# tviic2d6mddr register map
Vendor: Cypress Semiconductor; Series: tviic2d6mddr; File version: 1.0
CPU: CM7 r0p1, little endian, MPU, FPU, VTOR, 3 interrupt priority bits
Registers are 32-bit, read-write, reset 0x0 unless marked. A register's access mark holds for its fields unless they carry their own. Offsets are from the block's base; [hi:lo] are bit positions; lines under a group give offsets from that group; {n}, {i} and the like mark numbered series; 'fields as' and 'values as' point back to an identical list.

## LPDDR40 (part 4 of 5) — LPDDR4
Base 0x404A0000
0x1000 LPDDR4_CORE group — LPDDR4 core (3PIP)
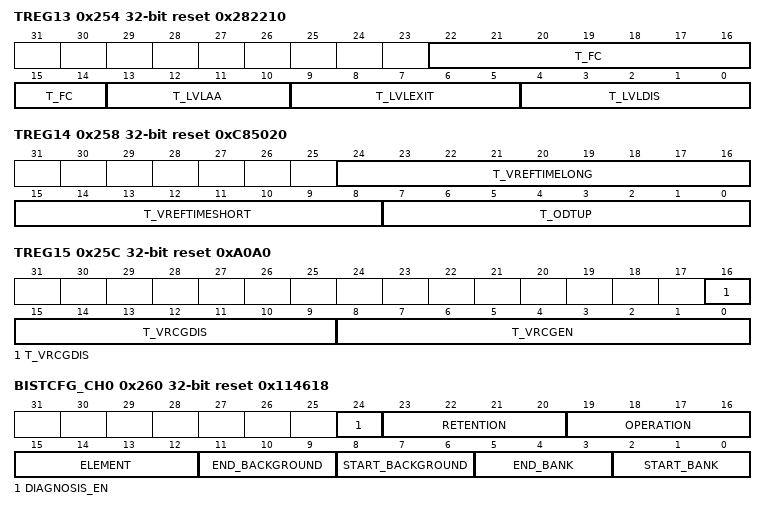
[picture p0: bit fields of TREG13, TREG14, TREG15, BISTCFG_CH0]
  0x254 TREG13 reset 0x282210 — Timing Register 13
    [22:14] T_FC — Frequency Set Point Switching Time = 'ha0
    [13:10] T_LVLAA — Leveling command-to-command/strobe-to-strobe delay. For read training, specifies the minimum number of DFI clock cycles after the assertion of a RD/MRR command to the next RD/MRR command. For write leveling, specifies the minimum number of DFI clock cycles after the assertion of the dfi_wrlvl_strobe signal to the next dfi_wrlvl_strobe signal assertion. = 8
    [9:5] T_LVLEXIT — Leveling exit time, specifies the minimum number of DFI clock cycles after the de-assertion of the DTI_*LVL_EN signal to the MRS command to disable DDR training. = 20
    [4:0] T_LVLDIS — Leveling disable time, specifies the minimum number of DFI clock cycles after the PHY asserts training status signal to the de-assert of DTI_*LVL_EN. = 8
  0x258 TREG14 reset 0xC85020 — Timing Register 14
    [24:16] T_VREFTIMELONG — VREF changing time for multiple steps >= RU(tVREFca_Long/tfs_period)
    [15:8] T_VREFTIMESHORT — VREF changing time for single steps. >= RU(tVREFca_Short/tfs_period)
    [7:0] T_ODTUP
  0x25C TREG15 reset 0xA0A0 — Timing Register 15
    [16:9] T_VRCGDIS — VREF high current mode disable time = 8'h53
    [8:0] T_VRCGEN — VREF high current mode enable time = 9'ha3
  0x260 BISTCFG_CH0 reset 0x114618 — BIST Configuration Register - Channel 0
    [24] DIAGNOSIS_EN — Enable diagnosis mode - Channel 0 Enable/disable coding: DISABLE = 0 Disable this feature ENABLE = 1 Enable this feature
    [23:20] RETENTION — Count-to value of retention counter (Width = RETENTION_WIDTH) - Channel 0
    [19:16] OPERATION — March operation number - Channel 0
    [15:12] ELEMENT — March element number - Channel 0
    [11:9] END_BACKGROUND — End background index - Channel 0
    [8:6] START_BACKGROUND — Start background index - Channel 0
    [5:3] END_BANK — End bank (Width = DRAM_BANK_WIDTH) - Channel 0
    [2:0] START_BANK — Start bank (Width = DRAM_BANK_WIDTH) - Channel 0
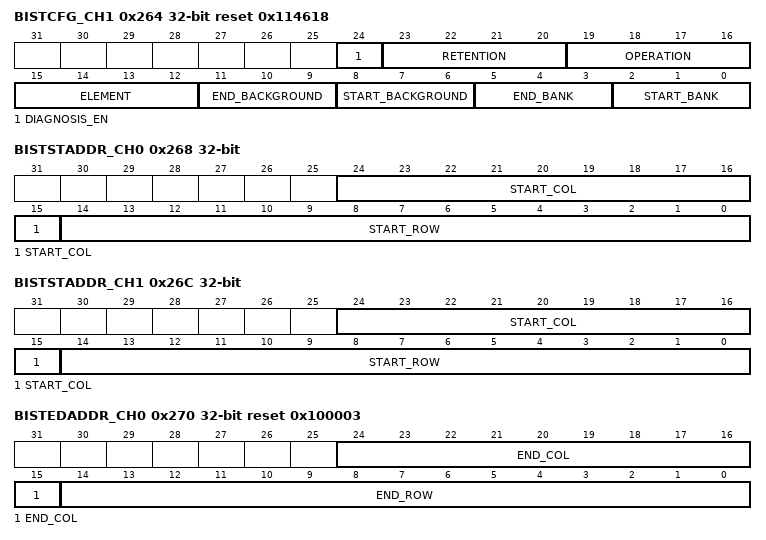
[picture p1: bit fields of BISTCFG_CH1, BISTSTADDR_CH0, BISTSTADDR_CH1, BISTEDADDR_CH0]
  0x264 BISTCFG_CH1 reset 0x114618 — BIST Configuration Register - Channel 1
    [24] DIAGNOSIS_EN — Enable diagnosis mode - Channel 1 Enable/disable coding: DISABLE = 0 Disable this feature ENABLE = 1 Enable this feature
    [23:20] RETENTION — Count-to value of retention counter (Width = RETENTION_WIDTH) - Channel 1
    [19:16] OPERATION — March operation number - Channel 1
    [15:12] ELEMENT — March element number - Channel 1
    [11:9] END_BACKGROUND — End background index - Channel 1
    [8:6] START_BACKGROUND — Start background index - Channel 1
    [5:3] END_BANK — End bank (Width = DRAM_BANK_WIDTH) - Channel 1
    [2:0] START_BANK — Start bank (Width = DRAM_BANK_WIDTH) - Channel 1
  0x268 BISTSTADDR_CH0 — BIST Start Address - Channel 0
    [24:15] START_COL — Start column address (Width = DRAM_COL_WIDTH) - Channel 0
    [14:0] START_ROW — Start row address (Width = DRAM_ROW_WIDTH) - Channel 0
  0x26C BISTSTADDR_CH1 — BIST Start Address - Channel 1
    [24:15] START_COL — Start column address (Width = DRAM_COL_WIDTH) - Channel 1
    [14:0] START_ROW — Start row address (Width = DRAM_ROW_WIDTH) - Channel 1
  0x270 BISTEDADDR_CH0 reset 0x100003 — BIST End Address - Channel 0
    [24:15] END_COL — End column address (Width = DRAM_COL_WIDTH) - Channel 0
    [14:0] END_ROW — End row address (Width = DRAM_ROW_WIDTH) - Channel 0
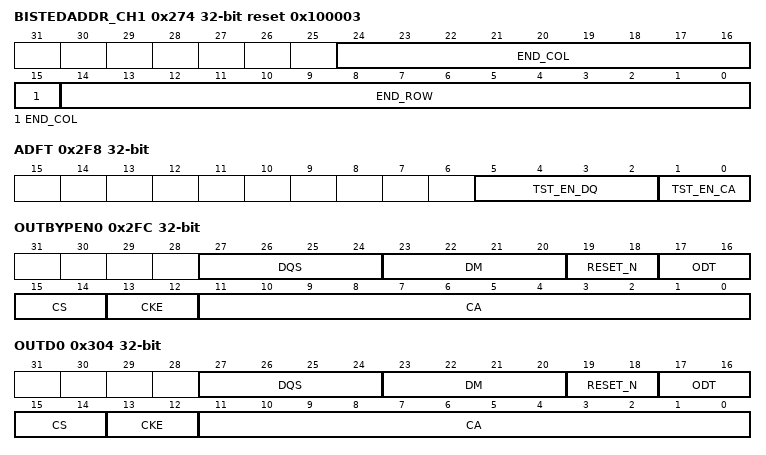
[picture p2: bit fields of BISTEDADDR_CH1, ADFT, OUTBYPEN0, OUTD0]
  0x274 BISTEDADDR_CH1 reset 0x100003 — BIST End Address - Channel 1
    [24:15] END_COL — End column address (Width = DRAM_COL_WIDTH) - Channel 1
    [14:0] END_ROW — End row address (Width = DRAM_ROW_WIDTH) - Channel 1
  0x278 BISTM0_CH0 reset 0x92000000 — BIST March Element Register 0 - Channel 0
    [31:0] MARCH_ELEMENT_0 — March element 0 - Channel 0
  0x27C BISTM0_CH1 reset 0x92000000 — BIST March Element Register 0 - Channel 1
    [31:0] MARCH_ELEMENT_0 — March element 0 - Channel 1
  0x280 BISTM1_CH0 reset 0xA0000000 — BIST March Element Register 1 - Channel 0
    [31:0] MARCH_ELEMENT_1 — March element 1 - Channel 0
  0x284 BISTM1_CH1 reset 0xA0000000 — BIST March Element Register 1 - Channel 1
    [31:0] MARCH_ELEMENT_1 — March element 1 - Channel 1
  0x288 BISTM2_CH0 reset 0xCA800000 — BIST March Element Register 2 - Channel 0
    [31:0] MARCH_ELEMENT_2 — March element 2 - Channel 0
  0x28C BISTM2_CH1 reset 0xCA800000 — BIST March Element Register 2 - Channel 1
    [31:0] MARCH_ELEMENT_2 — March element 2 - Channel 1
  0x290 BISTM3_CH0 reset 0x20000000 — BIST March Element Register 3 - Channel 0
    [31:0] MARCH_ELEMENT_3 — March element 3 - Channel 0
  0x294 BISTM3_CH1 reset 0x20000000 — BIST March Element Register 3 - Channel 1
    [31:0] MARCH_ELEMENT_3 — March element 3 - Channel 1
  0x298 BISTM4_CH0 reset 0x4E000000 — BIST March Element Register 4 - Channel 0
    [31:0] MARCH_ELEMENT_4 — March element 4 - Channel 0
  0x29C BISTM4_CH1 reset 0x4E000000 — BIST March Element Register 4 - Channel 1
    [31:0] MARCH_ELEMENT_4 — March element 4 - Channel 1
  {0x278+8j} BISTM{j}_CH0 (j=5..15) — BIST March Element Register {j} - Channel 0
    [31:0] MARCH_ELEMENT_{j} — March element {j} - Channel 0
  {0x27C+8j} BISTM{j}_CH1 (j=5..15) — BIST March Element Register {j} - Channel 1
    [31:0] MARCH_ELEMENT_{j} — March element {j} - Channel 1
  0x2F8 ADFT
    [5:2] TST_EN_DQ — Test enable for ADFT bus - DQ Blocks adft_tst_en_dq[0]: if set to 1: enable for VREF of Data Slice 0 adft_tst_en_dq[1]: if set to 1: enable for VREF of Data Slice 1 adft_tst_en_dq[2]: if set to 1: enable for VREF of Data Slice 2 adft_tst_en_dq[3]: if set to 1: enable for VREF of Data Slice 3
    [1:0] TST_EN_CA — Test enable for ADFT bus - Control Block adft_tst_en_ca[0]: if set to 1: enable for VREF of channel A adft_tst_en_ca[1]: if set to 1: enable for VREF of channel B
  0x2FC OUTBYPEN0 — Output Bypass Enable Register 0
    [27:24] DQS — Output Bypass Enable for DQS bus When a bit in register OUTBYPEN* is set to 1, the value of the corresponding bit in register OUTD* is asserted at the output.
    [23:20] DM — Output Bypass Enable for DM bus When a bit in register OUTBYPEN* is set to 1, the value of the corresponding bit in register OUTD* is asserted at the output.
    [19:18] RESET_N — Output Bypass Enable for RESET_N bus When a bit in register OUTBYPEN* is set to 1, the value of the corresponding bit in register OUTD* is asserted at the output.
    [17:16] ODT — Output Bypass Enable for ODT bus When a bit in register OUTBYPEN* is set to 1, the value of the corresponding bit in register OUTD* is asserted at the output.
    [15:14] CS — Output Bypass Enable for CS bus When a bit in register OUTBYPEN* is set to 1, the value of the corresponding bit in register OUTD* is asserted at the output.
    [13:12] CKE — Output Bypass Enable for CKE bus When a bit in register OUTBYPEN* is set to 1, the value of the corresponding bit in register OUTD* is asserted at the output.
    [11:0] CA — Output Bypass Enable for CA bus When a bit in register OUTBYPEN* is set to 1, the value of the corresponding bit in register OUTD* is asserted at the output.
  0x300 OUTBYPEN1 — Output Bypass Enable Register 1
    [31:0] DQ — Output Data Input for DQ bus When a bit in register OUTBYPEN* is set to 1, the value of the corresponding bit in register OUTD* is asserted at the output.
  0x304 OUTD0 — Output Data In Register 0
    [27:24] DQS — Output Data Input for DQS bus When a bit in register OUTBYPEN* is set to 1, the value of the corresponding bit in register OUTD* is asserted at the output.
    [23:20] DM — Output Data Input for DM bus When a bit in register OUTBYPEN* is set to 1, the value of the corresponding bit in register OUTD* is asserted at the output.
    [19:18] RESET_N — Output Data Input for RESET_N bus When a bit in register OUTBYPEN* is set to 1, the value of the corresponding bit in register OUTD* is asserted at the output.
    [17:16] ODT — Output Data Input for ODT bus When a bit in register OUTBYPEN* is set to 1, the value of the corresponding bit in register OUTD* is asserted at the output.
    [15:14] CS — Output Data Input for CS bus When a bit in register OUTBYPEN* is set to 1, the value of the corresponding bit in register OUTD* is asserted at the output.
    [13:12] CKE — Output Data Input for CKE bus When a bit in register OUTBYPEN* is set to 1, the value of the corresponding bit in register OUTD* is asserted at the output.
    [11:0] CA — Output Data Input for CA bus When a bit in register OUTBYPEN* is set to 1, the value of the corresponding bit in register OUTD* is asserted at the output.
  0x308 OUTD1 — Output Data In Register 1
    fields as LPDDR4_CORE.OUTBYPEN1
  0x30C INECC0 — Inline ECC Register 0
    [29:0] ECC_BASE — ECC Region Base Address
  0x310 INECC1 — Inline ECC Register 1
    [29:0] PROT_MEM_BASE — Protected Region Base Address
  0x314 INECC2 — Inline ECC Register 2
    [29:0] PROT_MEM_SIZE — Protected Region Size (Bytes)
  0xE00 DVSTT0 ro — Device ID Status Register
    [15:0] DEVICE_ID — 6 bits - Version, 5 bits - Reversion, 5 bits - Release
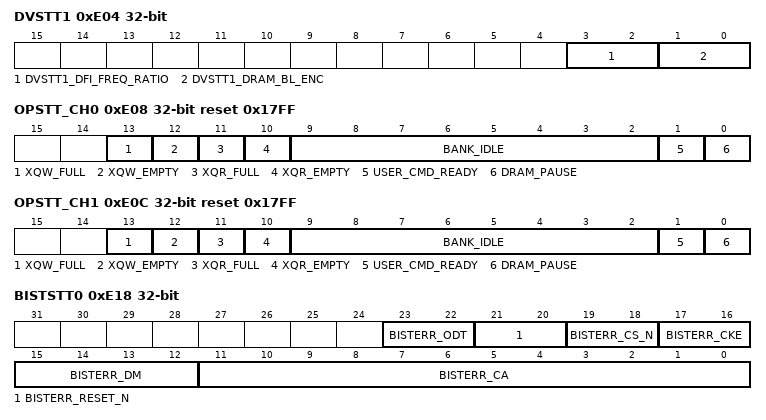
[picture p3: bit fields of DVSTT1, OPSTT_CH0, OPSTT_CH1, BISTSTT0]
  0xE04 DVSTT1 ro — Device Mode Status Register
    [3:2] DVSTT1_DFI_FREQ_RATIO — DFI frequency ratio. FREQ_RATIO_DIV4 = 2'b10 Always read 2'b10 as frequency ratio controller : PHY is fixed to 1:4
    [1:0] DVSTT1_DRAM_BL_ENC
  0xE08 OPSTT_CH0 ro reset 0x17FF — Operation Status Register 1 - Channel 0
    [13] XQW_FULL — Write Path Cross-over Queue Full - Channel 0
    [12] XQW_EMPTY — Write Path Cross-over Queue Empty - Channel 0
    [11] XQR_FULL — Read Path Cross-over Queue Full - Channel 0
    [10] XQR_EMPTY — Read Path Cross-over Queue Empty - Channel 0
    [9:2] BANK_IDLE — Bank Controller Idle (8 banks) - Channel 0
    [1] USER_CMD_READY — User Command Ready - Channel 0
    [0] DRAM_PAUSE — DRAM Paused for PD - Channel 0
  0xE0C OPSTT_CH1 ro reset 0x17FF — Operation Status Register 1 - Channel 1
    [13] XQW_FULL — Write Path Cross-over Queue Full - Channel 1
    [12] XQW_EMPTY — Write Path Cross-over Queue Empty - Channel 1
    [11] XQR_FULL — Read Path Cross-over Queue Full - Channel 1
    [10] XQR_EMPTY — Read Path Cross-over Queue Empty - Channel 1
    [9:2] BANK_IDLE — Bank Controller Idle (8 banks) - Channel 1
    [1] USER_CMD_READY — User Command Ready - Channel 1
    [0] DRAM_PAUSE — DRAM Paused for PD - Channel 1
  0xE10 INTSTT_CH0 ro — Interrupt Status Register - Channel 0
    [0] INT_GC_FSM — Global Control FSM Error Interrupt Status - Channel 0
  0xE14 INTSTT_CH1 ro — Interrupt Status Register - Channel 1
    [0] INT_GC_FSM — Global Control FSM Error Interrupt Status - Channel 1
  0xE18 BISTSTT0 ro — BIST Status 0
    [23:22] BISTERR_ODT — BIST Error status of ODT A '1' indicates an error on the respective ODT line.
    [21:20] BISTERR_RESET_N — BIST Error status of RESET_N A '1' indicates an error on the respective RST line.
    [19:18] BISTERR_CS_N — BIST Error status of CS_N A '1' indicates an error on the respective CS line.
    [17:16] BISTERR_CKE — BIST Error status of CKE A '1' indicates an error on the respective CKE line.
    [15:12] BISTERR_DM — BIST Error status of DM A '1' indicates an error on the respective DM line.
    [11:0] BISTERR_CA — BIST Error status of CA A '1' indicates an error on the respective CA line.
  0xE1C BISTSTT1 ro — BIST Status 1
    [31:0] BISTERR_DQ — BIST Error status of DQ Data Range A '1' indicates an error on the respective DQ line.
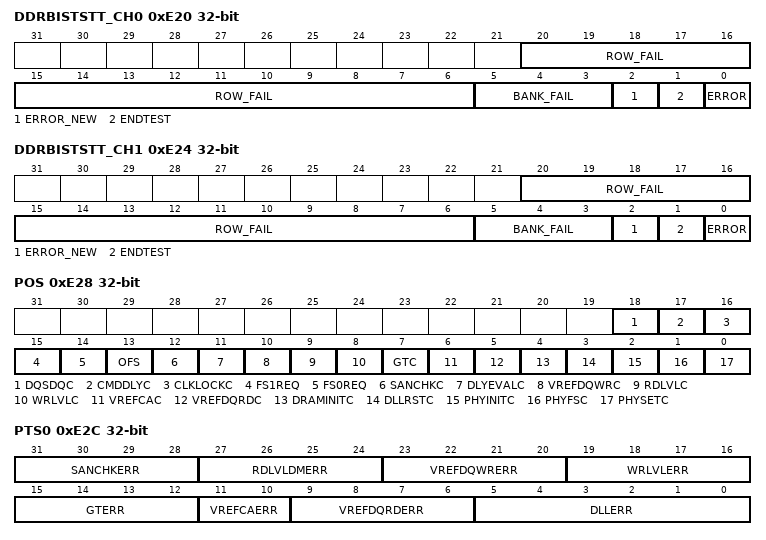
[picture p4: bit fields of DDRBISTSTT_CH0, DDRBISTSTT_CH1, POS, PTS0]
  0xE20 DDRBISTSTT_CH0 ro — DDR BIST Status Register - Channel 0
    [20:6] ROW_FAIL — Failed row address in diagnosis mode (Width = DRAM_ROW_WIDTH) - Channel 0
    [5:3] BANK_FAIL — Failed bank address in diagnosis mode (Width = DRAM_BANK_WIDTH) - Channel 0
    [2] ERROR_NEW — New BIST error in diagnosis mode - Channel 0
    [1] ENDTEST — BIST endtest - Channel 0
    [0] ERROR — BIST error - Channel 0
  0xE24 DDRBISTSTT_CH1 ro — DDR BIST Status Register - Channel 1
    [20:6] ROW_FAIL — Failed row address in diagnosis mode (Width = DRAM_ROW_WIDTH) - Channel 1
    [5:3] BANK_FAIL — Failed bank address in diagnosis mode (Width = DRAM_BANK_WIDTH) - Channel 1
    [2] ERROR_NEW — New BIST error in diagnosis mode - Channel 1
    [1] ENDTEST — BIST endtest - Channel 1
    [0] ERROR — BIST error - Channel 1
  0xE28 POS ro — PHY Operation Status Register
    [18] DQSDQC — tDQS2DQ training completed for rank 0
    [17] CMDDLYC — PHY command bus delay loaded
    [16] CLKLOCKC — MC-PHY clock phase locked.
    [15] FS1REQ — Frequency set point 1 request.
    [14] FS0REQ — Frequency set point 0 request.
    [13] OFS — Operating frequency set point.
    [12] SANCHKC — Write/read sanity check completed for rank 0
    [11] DLYEVALC — Delay evaluation completed for rank 0
    [10] VREFDQWRC — DRAM VREF-DQ training completed for rank 0
    [9] RDLVLC — Read data eye training completed for rank 0
    [8] WRLVLC — Write leveling completed for rank 0
    [7] GTC — Gate training completed for rank 0
    [6] VREFCAC — DRAM VREF-CA training completed.
    [5] VREFDQRDC — PHY VREF-DQ training completed.
    [4] DRAMINITC — DRAM initialization completed.
    [3] DLLRSTC — DLL reset completed.
    [2] PHYINITC — PHY initialization completed
    [1] PHYFSC — PHY frequency change completed.
    [0] PHYSETC — PHY setting reload completed.
  0xE2C PTS0 ro — PHY Training Status Register 0
    [31:28] SANCHKERR — Write/Read sanity check error on rank 0. One bit for each data slice. 1 means read pattern and write pattern for corresponding data slice are not match
    [27:24] RDLVLDMERR — DM read data eye training error on rank 0. One bit for each DM signal. 1 means data eye training for corresponding DM is not completed successfully
    [23:20] VREFDQWRERR — Write VREF-DQ training error on rank 0. One bit for each data slice. 1 means VREF training for DRAM is not completed successfully
    [19:16] WRLVLERR — Write leveling error on rank 0. One bit for each data slice. 1 means write leveling is not completed successfully
    [15:12] GTERR — Gate training error on rank 0. One bit for each data slice. 1 means gate training is not completed successfully
    [11:10] VREFCAERR — VREFCA training error on rank 0. vrefcaerr[1] is for LPDDR4 channel B and vrefcaerr[0] is for LPDDR4 channel A. 1 means VREFCA training for corresponding LPDDR4 channel is not completed successfully
    [9:6] VREFDQRDERR — Read VREF-DQ training error on rank 0. One bit for each data slice. 1 means PHY cannot find suitable VREF setting for its receiver
    [5:0] DLLERR — DLL reset error. Dllerr[3:0] is for data module [3:0], and dllerr[5:4] is for control module[1:0]. 1 means the DLL reset process of corresponding module is not completed successfully.
  0xE30 PTS1 ro — PHY Training Status Register 1
    [31:0] RDLVLDQERR — DQ read data eye training error on rank 0. One bit for each DQ signal. 1 means data eye training for corresponding DQ signal is not completed successfully.
  0xE34 PTS2 ro — PHY Training Status Register 2
    [31:0] DQSDQERR — DQS-DQ training error on rank 0. One bit for each DQ signal. 1 means data eye training for corresponding DQ signal is not completed successfully.
  0xE38 PTS3 ro — PHY Training Status Register 3
    [3:0] DQSDMERR — DQS-DM training error on rank 0. One bit for each DM signal. 1 means data eye training for corresponding DM signal is not completed successfully.
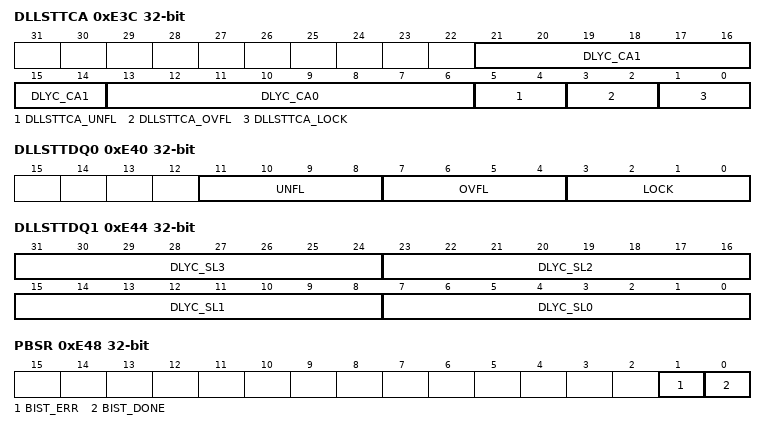
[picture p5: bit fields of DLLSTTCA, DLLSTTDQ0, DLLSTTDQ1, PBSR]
  0xE3C DLLSTTCA ro — DLL Status Register for PHY Command Module
    [21:14] DLYC_CA1 — DLL delay code for Channel B
    [13:6] DLYC_CA0 — DLL delay code for Channel A
    [5:4] DLLSTTCA_UNFL — Underflow status. This output is set when a quarter of the clock cycle is less than the shortest delay that the delay chain can handle.
    [3:2] DLLSTTCA_OVFL — Overflow status. This output is set when a quarter of the clock cycle is greater than the largest delay that the delay chain can handle.
    [1:0] DLLSTTCA_LOCK — DLL lock status.
  0xE40 DLLSTTDQ0 ro — DLL Status Register for PHY Data Module 0
    [11:8] UNFL — Underflow status. This output is set when a quarter of the clock cycle is less than the shortest delay that the delay chain can handle. One bit for each Data Slice.
    [7:4] OVFL — Overflow status. This output is set when a quarter of the clock cycle is greater than the largest delay that the delay chain can handle. One bit for each Data Slice.
    [3:0] LOCK — DLL lock status. One bit for each Data Slice.
  0xE44 DLLSTTDQ1 ro — DLL Status Register for PHY Data Module 1
    [8n+7:8n] DLYC_SL{n} (n=0..3) — DLL delay code DQ Slice {n}
  0xE48 PBSR ro — PHY BIST Status Register
    [1] BIST_ERR — PHY BIST error status
    [0] BIST_DONE — PHY BIST done status
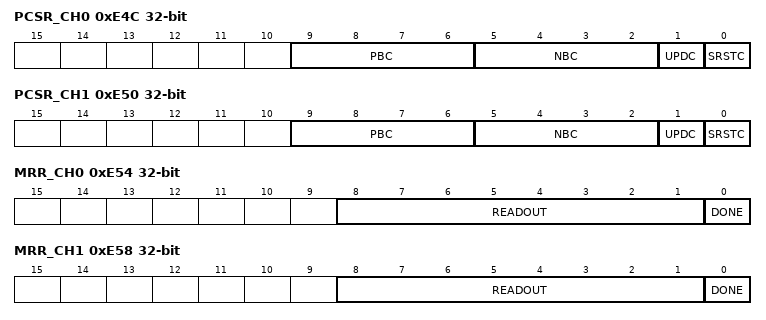
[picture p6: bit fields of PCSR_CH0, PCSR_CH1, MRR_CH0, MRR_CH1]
  0xE4C PCSR_CH0 ro — PHY Compensation Status Register - Channel 0
    [9:6] PBC — Impedance pull-up settings observation bits - Channel 0
    [5:2] NBC — Impedance pull-down settings observation bits - Channel 0
    [1] UPDC — Indicates if settings of the compensation were updated - Channel 0
    [0] SRSTC — Compensation soft-restart completed - Channel 0
  0xE50 PCSR_CH1 ro — PHY Compensation Status Register - Channel 1
    [9:6] PBC — Impedance pull-up settings observation bits - Channel 1
    [5:2] NBC — Impedance pull-down settings observation bits - Channel 1
    [1] UPDC — Indicates if settings of the compensation were updated - Channel 1
    [0] SRSTC — Compensation soft-restart completed - Channel 1
  0xE54 MRR_CH0 ro — MR Readout Register - Channel 0
    [8:1] READOUT — MRR data - Channel 0
    [0] DONE — MRR complete - Channel 0
  0xE58 MRR_CH1 ro — MR Readout Register - Channel 1
    [8:1] READOUT — MRR data - Channel 1
    [0] DONE — MRR complete - Channel 1
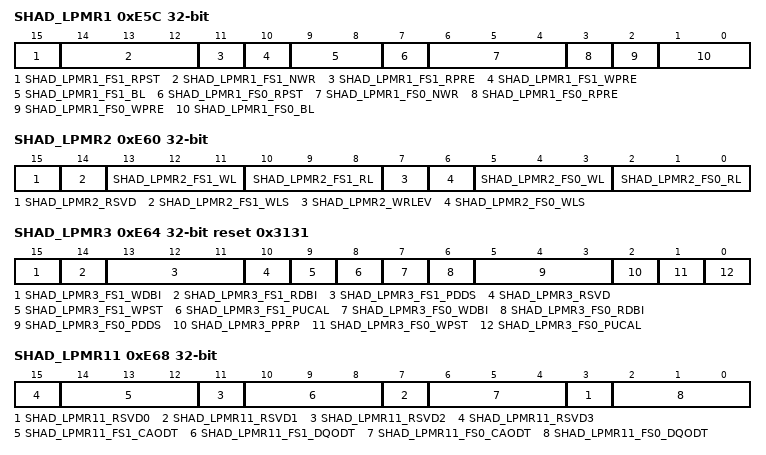
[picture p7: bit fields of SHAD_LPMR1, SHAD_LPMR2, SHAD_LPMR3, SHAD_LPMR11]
  0xE5C SHAD_LPMR1 ro — Shadow LPDDR Mode Register 1
    [15] SHAD_LPMR1_FS1_RPST — Shadow Read postamble FS1 Read Postamble values according to JESD209-4: RD_POSTAMBLE_0P5 = 0B RD Post-amble = 0.5*tCK (default) RD_POSTAMBLE_1P5 = 1B RD Post-amble = 1.5*tCK
    [14:12] SHAD_LPMR1_FS1_NWR — Shadow Write recovery to pre-charge FS1 Write Recovery values according to JESD209-4: NWR6 = 000B nWR = 6 (default) NWR10 = 001B nWR = 10 NWR16 = 010B nWR = 16 NWR20 = 011B nWR = 20 NWR24 = 100B nWR = 24 NWR30 = 101B nWR = 30 NWR34 = 110B nWR = 34 NWR40 = 111B nWR = 40
    [11] SHAD_LPMR1_FS1_RPRE — Shadow Read preamble FS1 Read Preamble values according to JESD209-4: RD_PREAMBLE_STATIC = 0B RD Pre-amble = Static (default) RD_PREAMBLE_TOGGLE = 1B RD Pre-amble = Toggle
    [10] SHAD_LPMR1_FS1_WPRE
    [9:8] SHAD_LPMR1_FS1_BL
    [7] SHAD_LPMR1_FS0_RPST — Shadow Read postamble FS0 Read Postamble values according to JESD209-4: RD_POSTAMBLE_0P5 = 0B RD Post-amble = 0.5*tCK (default) RD_POSTAMBLE_1P5 = 1B RD Post-amble = 1.5*tCK
    [6:4] SHAD_LPMR1_FS0_NWR — Shadow Write recovery to pre-charge FS0 Write Recovery values according to JESD209-4: NWR6 = 000B nWR = 6 (default) NWR10 = 001B nWR = 10 NWR16 = 010B nWR = 16 NWR20 = 011B nWR = 20 NWR24 = 100B nWR = 24 NWR30 = 101B nWR = 30 NWR34 = 110B nWR = 34 NWR40 = 111B nWR = 40
    [3] SHAD_LPMR1_FS0_RPRE — Shadow Read preamble FS0 Read Preamble values according to JESD209-4: RD_PREAMBLE_STATIC = 0B RD Pre-amble = Static (default) RD_PREAMBLE_TOGGLE = 1B RD Pre-amble = Toggle
    [2] SHAD_LPMR1_FS0_WPRE
    [1:0] SHAD_LPMR1_FS0_BL
  0xE60 SHAD_LPMR2 ro — Shadow LPDDR Mode Register 2
    [15] SHAD_LPMR2_RSVD
    [14] SHAD_LPMR2_FS1_WLS — Shadow Write latency set FS1 Values according to JESD209-4: WL_SET_A = 0B WL Set 'A' (default) WL_SET_B = 1B WL Set 'B'
    [13:11] SHAD_LPMR2_FS1_WL — Shadow Write latency FS1 Write Latency values according to JESD209-4: WL Set 'A' (MR2 OP[6]=0B) 000B: WL=4 (Default) 001B: WL=6 010B: WL=8 011B: WL=10 100B: WL=12 101B: WL=14 110B: WL=16 111B: WL=18 WL Set 'B' (MR2 OP[6]=1B) 000B: WL=4 001B: WL=8 010B: WL=12 011B: WL=18 100B: WL=22 101B: WL=26 110B: WL=30 111B: WL=34
    [10:8] SHAD_LPMR2_FS1_RL — Shadow Read latency FS1 Read Latency values according to JESD209-4: RL & nRTP for DBI-RD Disabled (MR3 OP[6]=0B) 000B: RL=6, nRTP = 8 (Default) 001B: RL=10, nRTP = 8 010B: RL=14, nRTP = 8 011B: RL=20, nRTP = 8 100B: RL=24, nRTP = 10 101B: RL=28, nRTP = 12 110B: RL=32, nRTP = 14 111B: RL=36, nRTP = 16 RL & nRTP for DBI-RD Enabled (MR3 OP[6]=1B) 000B: RL=6, nRTP = 8 001B: RL=12, nRTP = 8 010B: RL=16, nRTP = 8 011B: RL=22, nRTP = 8 100B: RL=28, nRTP = 10 101B: RL=32, nRTP = 12 110B: RL=36, nRTP = 14 111B: RL=40, nRTP = 16
    [7] SHAD_LPMR2_WRLEV — Shadow Write Leveling Enable FS0 Enable/disable coding: DISABLE = 0 Disable this feature ENABLE = 1 Enable this feature
    [6] SHAD_LPMR2_FS0_WLS — Shadow Write latency set FS0 Values according to JESD209-4: WL_SET_A = 0B WL Set 'A' (default) WL_SET_B = 1B WL Set 'B'
    [5:3] SHAD_LPMR2_FS0_WL — Shadow Write latency FS0 Write Latency values according to JESD209-4: WL Set 'A' (MR2 OP[6]=0B) 000B: WL=4 (Default) 001B: WL=6 010B: WL=8 011B: WL=10 100B: WL=12 101B: WL=14 110B: WL=16 111B: WL=18 WL Set 'B' (MR2 OP[6]=1B) 000B: WL=4 001B: WL=8 010B: WL=12 011B: WL=18 100B: WL=22 101B: WL=26 110B: WL=30 111B: WL=34
    [2:0] SHAD_LPMR2_FS0_RL — Shadow Read latency FS0 Read Latency values according to JESD209-4: RL & nRTP for DBI-RD Disabled (MR3 OP[6]=0B) 000B: RL=6, nRTP = 8 (Default) 001B: RL=10, nRTP = 8 010B: RL=14, nRTP = 8 011B: RL=20, nRTP = 8 100B: RL=24, nRTP = 10 101B: RL=28, nRTP = 12 110B: RL=32, nRTP = 14 111B: RL=36, nRTP = 16 RL & nRTP for DBI-RD Enabled (MR3 OP[6]=1B) 000B: RL=6, nRTP = 8 001B: RL=12, nRTP = 8 010B: RL=16, nRTP = 8 011B: RL=22, nRTP = 8 100B: RL=28, nRTP = 10 101B: RL=32, nRTP = 12 110B: RL=36, nRTP = 14 111B: RL=40, nRTP = 16
  0xE64 SHAD_LPMR3 ro reset 0x3131 — Shadow LPDDR Mode Register 3
    [15] SHAD_LPMR3_FS1_WDBI — Write DBI mode for frequency set 1 Values according to JESD209-4: Enable/disable coding: DISABLE = 0 Disable this feature ENABLE = 1 Enable this feature
    [14] SHAD_LPMR3_FS1_RDBI — Read DBI mode for frequency set 1 Values according to JESD209-4: Enable/disable coding: DISABLE = 0 Disable this feature ENABLE = 1 Enable this feature
    [13:11] SHAD_LPMR3_FS1_PDDS
    [10] SHAD_LPMR3_RSVD
    [9] SHAD_LPMR3_FS1_WPST — Write post-amble for frequency set 1 Write post-amble values according to JESD209-4: WR_POSTAMBLE_0P5 = 0B WR Post-amble = 0.5*tCK (default) WR_POSTAMBLE_1P5 = 1B WR Post-amble = 1.5*tCK (Vendor specific function)
    [8] SHAD_LPMR3_FS1_PUCAL — Pull-up Calibration point for frequency set 1 Pull-up Calibration point values according to JESD209-4: VDDQ_DIV_2P5 = 0B VDDQ/2.5 VDDQ_DIV_3 = 1B VDDQ/3 (default)
    [7] SHAD_LPMR3_FS0_WDBI — Write DBI mode for frequency set 0 Values according to JESD209-4: Enable/disable coding: DISABLE = 0 Disable this feature ENABLE = 1 Enable this feature
    [6] SHAD_LPMR3_FS0_RDBI — Read DBI mode for frequency set 0 Values according to JESD209-4: Enable/disable coding: DISABLE = 0 Disable this feature ENABLE = 1 Enable this feature
    [5:3] SHAD_LPMR3_FS0_PDDS
    [2] SHAD_LPMR3_PPRP — Post package repair protection Values according to JESD209-4: Enable/disable coding: DISABLE = 0 Disable this feature ENABLE = 1 Enable this feature
    [1] SHAD_LPMR3_FS0_WPST — Write post-amble for frequency set 0 Write post-amble values according to JESD209-4: WR_POSTAMBLE_0P5 = 0B WR Post-amble = 0.5*tCK (default) WR_POSTAMBLE_1P5 = 1B WR Post-amble = 1.5*tCK (Vendor specific function)
    [0] SHAD_LPMR3_FS0_PUCAL — Pull-up Calibration point for frequency set 0 Pull-up Calibration point values according to JESD209-4: VDDQ_DIV_2P5 = 0B VDDQ/2.5 VDDQ_DIV_3 = 1B VDDQ/3 (default)
  0xE68 SHAD_LPMR11 ro — Shadow LPDDR Mode Register 11
    [4n+3] SHAD_LPMR11_RSVD{n} (n=0..3), [14:12] SHAD_LPMR11_FS1_CAODT, [10:8] SHAD_LPMR11_FS1_DQODT, [6:4] SHAD_LPMR11_FS0_CAODT, [2:0] SHAD_LPMR11_FS0_DQODT
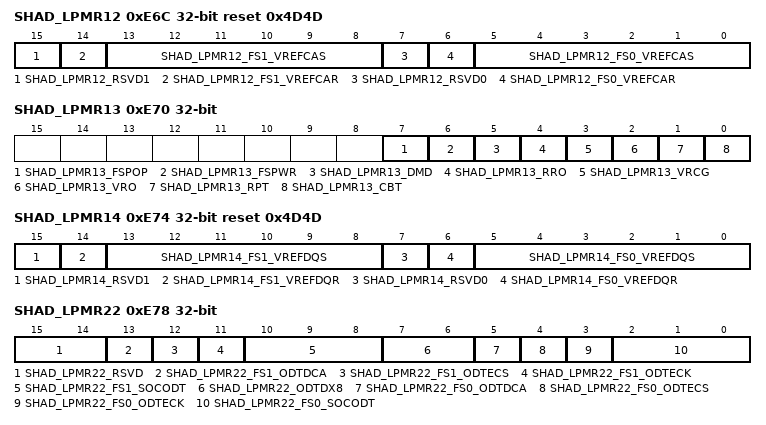
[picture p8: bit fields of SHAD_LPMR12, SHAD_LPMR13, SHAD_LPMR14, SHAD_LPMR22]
  0xE6C SHAD_LPMR12 ro reset 0x4D4D — Shadow LPDDR Mode Register 12
    [15] SHAD_LPMR12_RSVD1
    [14] SHAD_LPMR12_FS1_VREFCAR — VREF-CA range for frequency set 1 VREF Range according to JESD209-4: RANGE0 = 0B Range[0] enabled RANGE1 =1B Range[1] enabled
    [13:8] SHAD_LPMR12_FS1_VREFCAS — VREF-CA Settings for frequency set 1 VREF-CA Setting values according to JESD209-4: See JESD209-4B Table 13 - VREF Settings for Range[0] and Range[1]
    [7] SHAD_LPMR12_RSVD0
    [6] SHAD_LPMR12_FS0_VREFCAR — VREF-CA range for frequency set 0 VREF Range according to JESD209-4: RANGE0 = 0B Range[0] enabled RANGE1 =1B Range[1] enabled
    [5:0] SHAD_LPMR12_FS0_VREFCAS — VREF-CA Settings for frequency set 0 VREF-CA Setting values according to JESD209-4: See JESD209-4B Table 13 - VREF Settings for Range[0] and Range[1]
  0xE70 SHAD_LPMR13 ro — Shadow LPDDR Mode Register 13
    [7] SHAD_LPMR13_FSPOP — Frequency Set Point operating mode Frequency Set Point coding according to JESD209-4: FSP0 = 0 Frequency Set Point 0 FSP1 = 1 Frequency Set Point 1
    [6] SHAD_LPMR13_FSPWR — Frequency Set Point write enable Frequency Set Point coding according to JESD209-4: FSP0 = 0 Frequency Set Point 0 FSP1 = 1 Frequency Set Point 1
    [5] SHAD_LPMR13_DMD — Data mask disable Data Mask Disable values according to JESD209-4: ENABLED = 0B Data Mask Operation Enabled (default) DISABLED = 1B Data Mask Operation Disabled
    [4] SHAD_LPMR13_RRO — Refresh rate option Refresh Rate Option values according to JESD209-4: DISABLE_RR4X2X = 0B Disable codes 001 (Refresh Rate x 4) and 010 (Refresh Rate x 2) in MR4 OP[2:0] ENABLE_ALL = 1B Enable all codes in MR4 OP[2:0]
    [3] SHAD_LPMR13_VRCG — VREF current generator VREF Current Generator values according to JESD209-4: NORMAL = 0B Normal Operation (default) VREF_FAST = 1B VREF Fast Response (high current) mode
    [2] SHAD_LPMR13_VRO — VREF output enable Enable/disable coding: DISABLE = 0 Disable this feature ENABLE = 1 Enable this feature
    [1] SHAD_LPMR13_RPT — Read preamble training mode Values according to JESD209-4: Enable/disable coding: DISABLE = 0 Disable this feature ENABLE = 1 Enable this feature
    [0] SHAD_LPMR13_CBT — Command bus training mode enable Enable/disable coding: DISABLE = 0 Disable this feature ENABLE = 1 Enable this feature
  0xE74 SHAD_LPMR14 ro reset 0x4D4D — Shadow LPDDR Mode Register 14
    [15] SHAD_LPMR14_RSVD1
    [14] SHAD_LPMR14_FS1_VREFDQR — VREF-DQ range for frequency set 1 VREF Range according to JESD209-4: RANGE0 = 0B Range[0] enabled RANGE1 =1B Range[1] enabled
    [13:8] SHAD_LPMR14_FS1_VREFDQS — VREF-DQ Settings for frequency set 1 VREF-DQ Setting values according to JESD209-4: See JESD209-4B Table 14 - VREF Settings for Range[0] and Range[1]
    [7] SHAD_LPMR14_RSVD0
    [6] SHAD_LPMR14_FS0_VREFDQR — VREF-DQ range for frequency set 0 VREF Range according to JESD209-4: RANGE0 = 0B Range[0] enabled RANGE1 =1B Range[1] enabled
    [5:0] SHAD_LPMR14_FS0_VREFDQS — VREF-DQ Settings for frequency set 0 VREF-DQ Setting values according to JESD209-4: See JESD209-4B Table 14 - VREF Settings for Range[0] and Range[1]
  0xE78 SHAD_LPMR22 ro — Shadow LPDDR Mode Register 22
    [15:14] SHAD_LPMR22_RSVD
    [13] SHAD_LPMR22_FS1_ODTDCA — ODTD-CA. CA ODT termination disable for frequency set 1 Command/Address bus ODT termination disable. Values according to JESD209-4: ODT_CA_PAD = 0B ODT-CA Obeys ODT_CA bond pad (default) ODT_CA_DISABLED = 1B ODT-CA Disabled
    [12] SHAD_LPMR22_FS1_ODTECS — ODTE-CS. CS ODT enable for non-terminating rank for frequency set 1 ODT Enable for non-terminating rank. Values according to JESD209-4: OVERRIDE_DISABLED = 0B ODT-CK Over-ride Disabled (Default) OVERRIDE_ENABLED = 1B ODT-CK Over-ride Enabled
    [11] SHAD_LPMR22_FS1_ODTECK — ODTE-CK. CK ODT enable for non-terminating rank for frequency set 1 ODT Enable for non-terminating rank. Values according to JESD209-4: OVERRIDE_DISABLED = 0B ODT-CK Over-ride Disabled (Default) OVERRIDE_ENABLED = 1B ODT-CK Over-ride Enabled
    [10:8] SHAD_LPMR22_FS1_SOCODT — SoC ODT. Controller ODT value for VOH calibration for frequency set 1 Controller ODT values according to JESD209-4: DISABLE = 000B Disable (Default) RZQ_DIV_1 = 001B RZQ/1 RZQ_DIV_2 = 010B RZQ/2 RZQ_DIV_3 = 011B RZQ/3 RZQ_DIV_4 = 100B RZQ/4 RZQ_DIV_5 = 101B RZQ/5 RZQ_DIV_6 = 110B RZQ/6 RFU = 111B RFU
    [7:6] SHAD_LPMR22_ODTDX8 — ODTD for x8_2ch (byte) mode
    [5] SHAD_LPMR22_FS0_ODTDCA — ODTD-CA. CA ODT termination disable for frequency set 0 Command/Address bus ODT termination disable. Values according to JESD209-4: ODT_CA_PAD = 0B ODT-CA Obeys ODT_CA bond pad (default) ODT_CA_DISABLED = 1B ODT-CA Disabled
    [4] SHAD_LPMR22_FS0_ODTECS — ODTE-CS. CS ODT enable for non-terminating rank for frequency set 0 ODT Enable for non-terminating rank. Values according to JESD209-4: OVERRIDE_DISABLED = 0B ODT-CK Over-ride Disabled (Default) OVERRIDE_ENABLED = 1B ODT-CK Over-ride Enabled
    [3] SHAD_LPMR22_FS0_ODTECK — ODTE-CK. CK ODT enable for non-terminating rank for frequency set 0 ODT Enable for non-terminating rank. Values according to JESD209-4: OVERRIDE_DISABLED = 0B ODT-CK Over-ride Disabled (Default) OVERRIDE_ENABLED = 1B ODT-CK Over-ride Enabled
    [2:0] SHAD_LPMR22_FS0_SOCODT — SoC ODT. Controller ODT value for VOH calibration for frequency set 0 Controller ODT values according to JESD209-4: DISABLE = 000B Disable (Default) RZQ_DIV_1 = 001B RZQ/1 RZQ_DIV_2 = 010B RZQ/2 RZQ_DIV_3 = 011B RZQ/3 RZQ_DIV_4 = 100B RZQ/4 RZQ_DIV_5 = 101B RZQ/5 RZQ_DIV_6 = 110B RZQ/6 RFU = 111B RFU
  0xE7C RESP ro — PHY Response Register
    [31:0] RESP_WRLEV — Write Leveling Response Voltage levels can be swept on the PAD_DQ and the receiver response is observable in this register
  {0xE80+4j} DATA{j} ro (j=0..7) — Read Data Register {j}
    [31:0] RDDATA — Read Data [{32j+31}:{32j}] for Loopback test mode
  0xEA0 DATA8 ro — Read Data Register 8
    [0] RDVALID — Read Data Valid, active HIGH. When this field is HIGH: - User can read out RDDATA from data registers DATA0 ... DATA8 - This field will be cleared automatically after user read it out
  0xEA4 INECCSTT0 ro — Inline ECC Status Register 0
    [29:0] ECC_ERROR_ADDR — ECC Error FIFO: Address of the DRAM access causing the ECC error. One AXI4 Request can be split into 2 DRAM requests if the AXI4 address is unaligned to 32-byte. This register stores the address of DRAM request.
  0xEA8 INECCSTT1 ro — Inline ECC Status Register 1
    [31:0] ECC_ERROR_SYNDROME — ECC Error FIFO: Four syndromes of a DRAM Request. Each 8-bit syndrome corresponds to 64-bit data
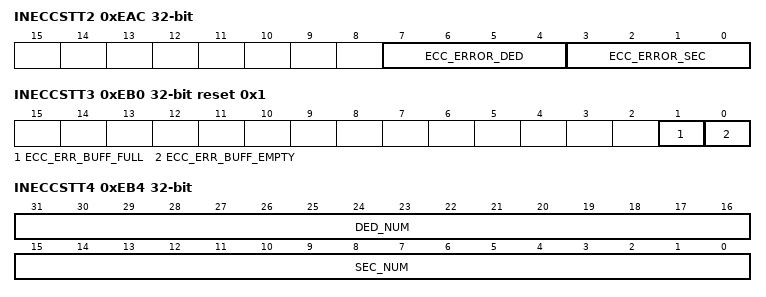
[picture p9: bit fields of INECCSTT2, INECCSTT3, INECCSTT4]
  0xEAC INECCSTT2 ro — Inline ECC Status Register 2
    [7:4] ECC_ERROR_DED — ECC Error FIFO: Four DED bits of a DRAM Request. Each bit corresponds to 64-bit data.
    [3:0] ECC_ERROR_SEC — ECC Error FIFO: Four SEC bits of a DRAM Request. Each bit corresponds to 64-bit data.
  0xEB0 INECCSTT3 ro reset 0x1 — Inline ECC Status Register 3
    [1] ECC_ERR_BUFF_FULL — ECC Information Buffer Full Flag NO = 0 The FIFO is not full YES = 1 The FIFO is full, the FIFO cannot collect the information of new errors
    [0] ECC_ERR_BUFF_EMPTY — ECC Information Buffer Empty Flag NO = 0 The FIFO is not empty, some data errors occur YES = 1 The FIFO is empty, no error occurs
  0xEB4 INECCSTT4 — Inline ECC Status Register 4
    [31:16] DED_NUM — Number of DED Write to this register to clear the value
    [15:0] SEC_NUM — Number of SEC Write to this register to clear the value
